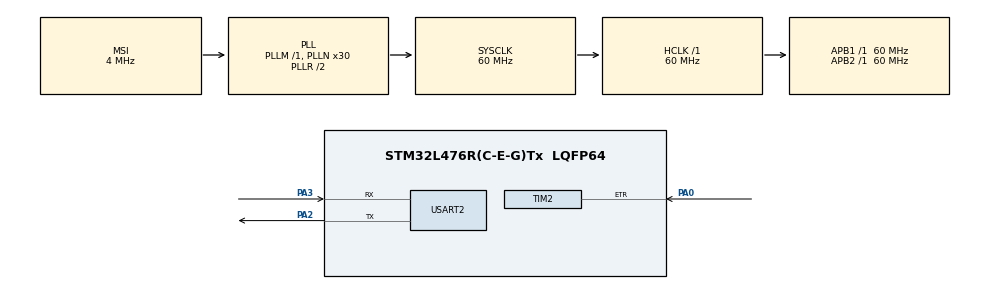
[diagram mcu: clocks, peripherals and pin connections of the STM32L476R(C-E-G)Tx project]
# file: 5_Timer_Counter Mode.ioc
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Mcu.Family=STM32L4
Mcu.Name=STM32L476R(C-E-G)Tx
Mcu.Package=LQFP64
NVIC.PriorityGroup=NVIC_PRIORITYGROUP_4
NVIC.TIM2_IRQn=true\:0\:0\:false\:false\:true\:true\:true\:true
PA0.Signal=S_TIM2_ETR
PA2.Mode=Asynchronous
PA2.Signal=USART2_TX
PA3.Mode=Asynchronous
PA3.Signal=USART2_RX
ProjectManager.HeapSize=0x200
ProjectManager.StackSize=0x400
ProjectManager.TargetToolchain=STM32CubeIDE
RCC.AHBFreq_Value=60000000
RCC.APB1Freq_Value=60000000
RCC.APB1TimFreq_Value=60000000
RCC.APB2Freq_Value=60000000
RCC.APB2TimFreq_Value=60000000
RCC.CortexFreq_Value=60000000
RCC.HCLKFreq_Value=60000000
RCC.HSE_VALUE=8000000
RCC.HSI_VALUE=16000000
RCC.LSE_VALUE=32768
RCC.MSI_VALUE=4000000
RCC.PLLN=30
RCC.SYSCLKFreq_VALUE=60000000
RCC.SYSCLKSource=RCC_SYSCLKSOURCE_PLLCLK
RCC.VCOOutputFreq_Value=120000000
SH.S_TIM2_ETR.0=TIM2_ETR,ClockSourceETR_Mode2
TIM2.AutoReloadPreload=TIM_AUTORELOAD_PRELOAD_ENABLE
TIM2.Period=100
TIM2.Prescaler=60-1
USART2.VirtualMode-Asynchronous=VM_ASYNC
board=custom

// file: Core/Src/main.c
/* USER CODE BEGIN Header */
/**
  ******************************************************************************
  * @file           : main.c
  * @brief          : Main program body
  ******************************************************************************
  * @attention
  *
  * Copyright (c) 2024 STMicroelectronics.
  * All rights reserved.
  *
  * This software is licensed under terms that can be found in the LICENSE file
  * in the root directory of this software component.
  * If no LICENSE file comes with this software, it is provided AS-IS.
  *
  ******************************************************************************

  - Timer 2 is used in counter mode with an external clock source ETR connected to PA0
  - Connect a Push button to PA0 and use it to increment the timer
  - The auto Reload Register is set to 99 and the timer interrupt is enabled to be fired once the timer overflows.
  - For console visualization we are using the the callback HAL_TIM_PeriodElapsedCallback function to send a message over UART.

  */
/* USER CODE END Header */
#include "main.h"

TIM_HandleTypeDef htim2;

UART_HandleTypeDef huart2;

/* USER CODE BEGIN PV */
uint8_t end_message[40] = "Overflow Reached! Counter is Reset\n\r";

/* USER CODE END PV */

void SystemClock_Config(void);
static void MX_GPIO_Init(void);
static void MX_TIM2_Init(void);
static void MX_USART2_UART_Init(void);
/* USER CODE BEGIN PFP */
void HAL_TIM_PeriodElapsedCallback(TIM_HandleTypeDef* htim);

/* USER CODE END PFP */

int main(void)
{
  /* USER CODE BEGIN 1 */
  uint8_t message[20] = {'\0'};
  uint16_t tick_count = 0;

  /* USER CODE END 1 */

  /* MCU Configuration--------------------------------------------------------*/

  /* Reset of all peripherals, Initializes the Flash interface and the Systick. */
  HAL_Init();

  /* Configure the system clock */
  SystemClock_Config();

  /* Initialize all configured peripherals */
  MX_GPIO_Init();
  MX_TIM2_Init();
  MX_USART2_UART_Init();
  /* USER CODE BEGIN 2 */
  HAL_TIM_Base_Start_IT(&htim2);

  /* USER CODE END 2 */

  /* Infinite loop */
  while (1)
  {

    /* USER CODE BEGIN 3 */
    tick_count = TIM2->CNT;
    sprintf(message, "Tick Count = %d\n\r", tick_count);
    HAL_UART_Transmit(&huart2, message, sizeof(message), 100);
    HAL_Delay(100);
  }
  /* USER CODE END 3 */
}

void SystemClock_Config(void)
{
  RCC_OscInitTypeDef RCC_OscInitStruct = {0};
  RCC_ClkInitTypeDef RCC_ClkInitStruct = {0};

  /** Configure the main internal regulator output voltage
  */
  if (HAL_PWREx_ControlVoltageScaling(PWR_REGULATOR_VOLTAGE_SCALE1) != HAL_OK)
  {
    Error_Handler();
  }

  /** Initializes the RCC Oscillators according to the specified parameters
  * in the RCC_OscInitTypeDef structure.
  */
  RCC_OscInitStruct.OscillatorType = RCC_OSCILLATORTYPE_MSI;
  RCC_OscInitStruct.MSIState = RCC_MSI_ON;
  RCC_OscInitStruct.MSICalibrationValue = 0;
  RCC_OscInitStruct.MSIClockRange = RCC_MSIRANGE_6;
  RCC_OscInitStruct.PLL.PLLState = RCC_PLL_ON;
  RCC_OscInitStruct.PLL.PLLSource = RCC_PLLSOURCE_MSI;
  RCC_OscInitStruct.PLL.PLLM = 1;
  RCC_OscInitStruct.PLL.PLLN = 30;
  RCC_OscInitStruct.PLL.PLLP = RCC_PLLP_DIV7;
  RCC_OscInitStruct.PLL.PLLQ = RCC_PLLQ_DIV2;
  RCC_OscInitStruct.PLL.PLLR = RCC_PLLR_DIV2;
  if (HAL_RCC_OscConfig(&RCC_OscInitStruct) != HAL_OK)
  {
    Error_Handler();
  }

  /** Initializes the CPU, AHB and APB buses clocks
  */
  RCC_ClkInitStruct.ClockType = RCC_CLOCKTYPE_HCLK|RCC_CLOCKTYPE_SYSCLK
                              |RCC_CLOCKTYPE_PCLK1|RCC_CLOCKTYPE_PCLK2;
  RCC_ClkInitStruct.SYSCLKSource = RCC_SYSCLKSOURCE_PLLCLK;
  RCC_ClkInitStruct.AHBCLKDivider = RCC_SYSCLK_DIV1;
  RCC_ClkInitStruct.APB1CLKDivider = RCC_HCLK_DIV1;
  RCC_ClkInitStruct.APB2CLKDivider = RCC_HCLK_DIV1;

  if (HAL_RCC_ClockConfig(&RCC_ClkInitStruct, FLASH_LATENCY_3) != HAL_OK)
  {
    Error_Handler();
  }
}

static void MX_TIM2_Init(void)
{

  TIM_ClockConfigTypeDef sClockSourceConfig = {0};
  TIM_MasterConfigTypeDef sMasterConfig = {0};

  htim2.Instance = TIM2;
  htim2.Init.Prescaler = 60-1;
  htim2.Init.CounterMode = TIM_COUNTERMODE_UP;
  htim2.Init.Period = 99;
  htim2.Init.ClockDivision = TIM_CLOCKDIVISION_DIV1;
  htim2.Init.AutoReloadPreload = TIM_AUTORELOAD_PRELOAD_ENABLE;
  if (HAL_TIM_Base_Init(&htim2) != HAL_OK)
  {
    Error_Handler();
  }
  sClockSourceConfig.ClockSource = TIM_CLOCKSOURCE_ETRMODE2;
  sClockSourceConfig.ClockPolarity = TIM_CLOCKPOLARITY_NONINVERTED;
  sClockSourceConfig.ClockPrescaler = TIM_CLOCKPRESCALER_DIV1;
  sClockSourceConfig.ClockFilter = 0;
  if (HAL_TIM_ConfigClockSource(&htim2, &sClockSourceConfig) != HAL_OK)
  {
    Error_Handler();
  }
  sMasterConfig.MasterOutputTrigger = TIM_TRGO_RESET;
  sMasterConfig.MasterSlaveMode = TIM_MASTERSLAVEMODE_DISABLE;
  if (HAL_TIMEx_MasterConfigSynchronization(&htim2, &sMasterConfig) != HAL_OK)
  {
    Error_Handler();
  }

}

static void MX_USART2_UART_Init(void)
{

  huart2.Instance = USART2;
  huart2.Init.BaudRate = 115200;
  huart2.Init.WordLength = UART_WORDLENGTH_8B;
  huart2.Init.StopBits = UART_STOPBITS_1;
  huart2.Init.Parity = UART_PARITY_NONE;
  huart2.Init.Mode = UART_MODE_TX_RX;
  huart2.Init.HwFlowCtl = UART_HWCONTROL_NONE;
  huart2.Init.OverSampling = UART_OVERSAMPLING_16;
  huart2.Init.OneBitSampling = UART_ONE_BIT_SAMPLE_DISABLE;
  huart2.AdvancedInit.AdvFeatureInit = UART_ADVFEATURE_NO_INIT;
  if (HAL_UART_Init(&huart2) != HAL_OK)
  {
    Error_Handler();
  }

}

static void MX_GPIO_Init(void)
{

  /* GPIO Ports Clock Enable */
  __HAL_RCC_GPIOA_CLK_ENABLE();

}

/* USER CODE BEGIN 4 */

void HAL_TIM_PeriodElapsedCallback(TIM_HandleTypeDef* htim)
{
    HAL_UART_Transmit(&huart2, end_message, sizeof(end_message), 100);
}

/* USER CODE END 4 */

void Error_Handler(void)
{
  __disable_irq();
  while (1)
  {
  }
}
